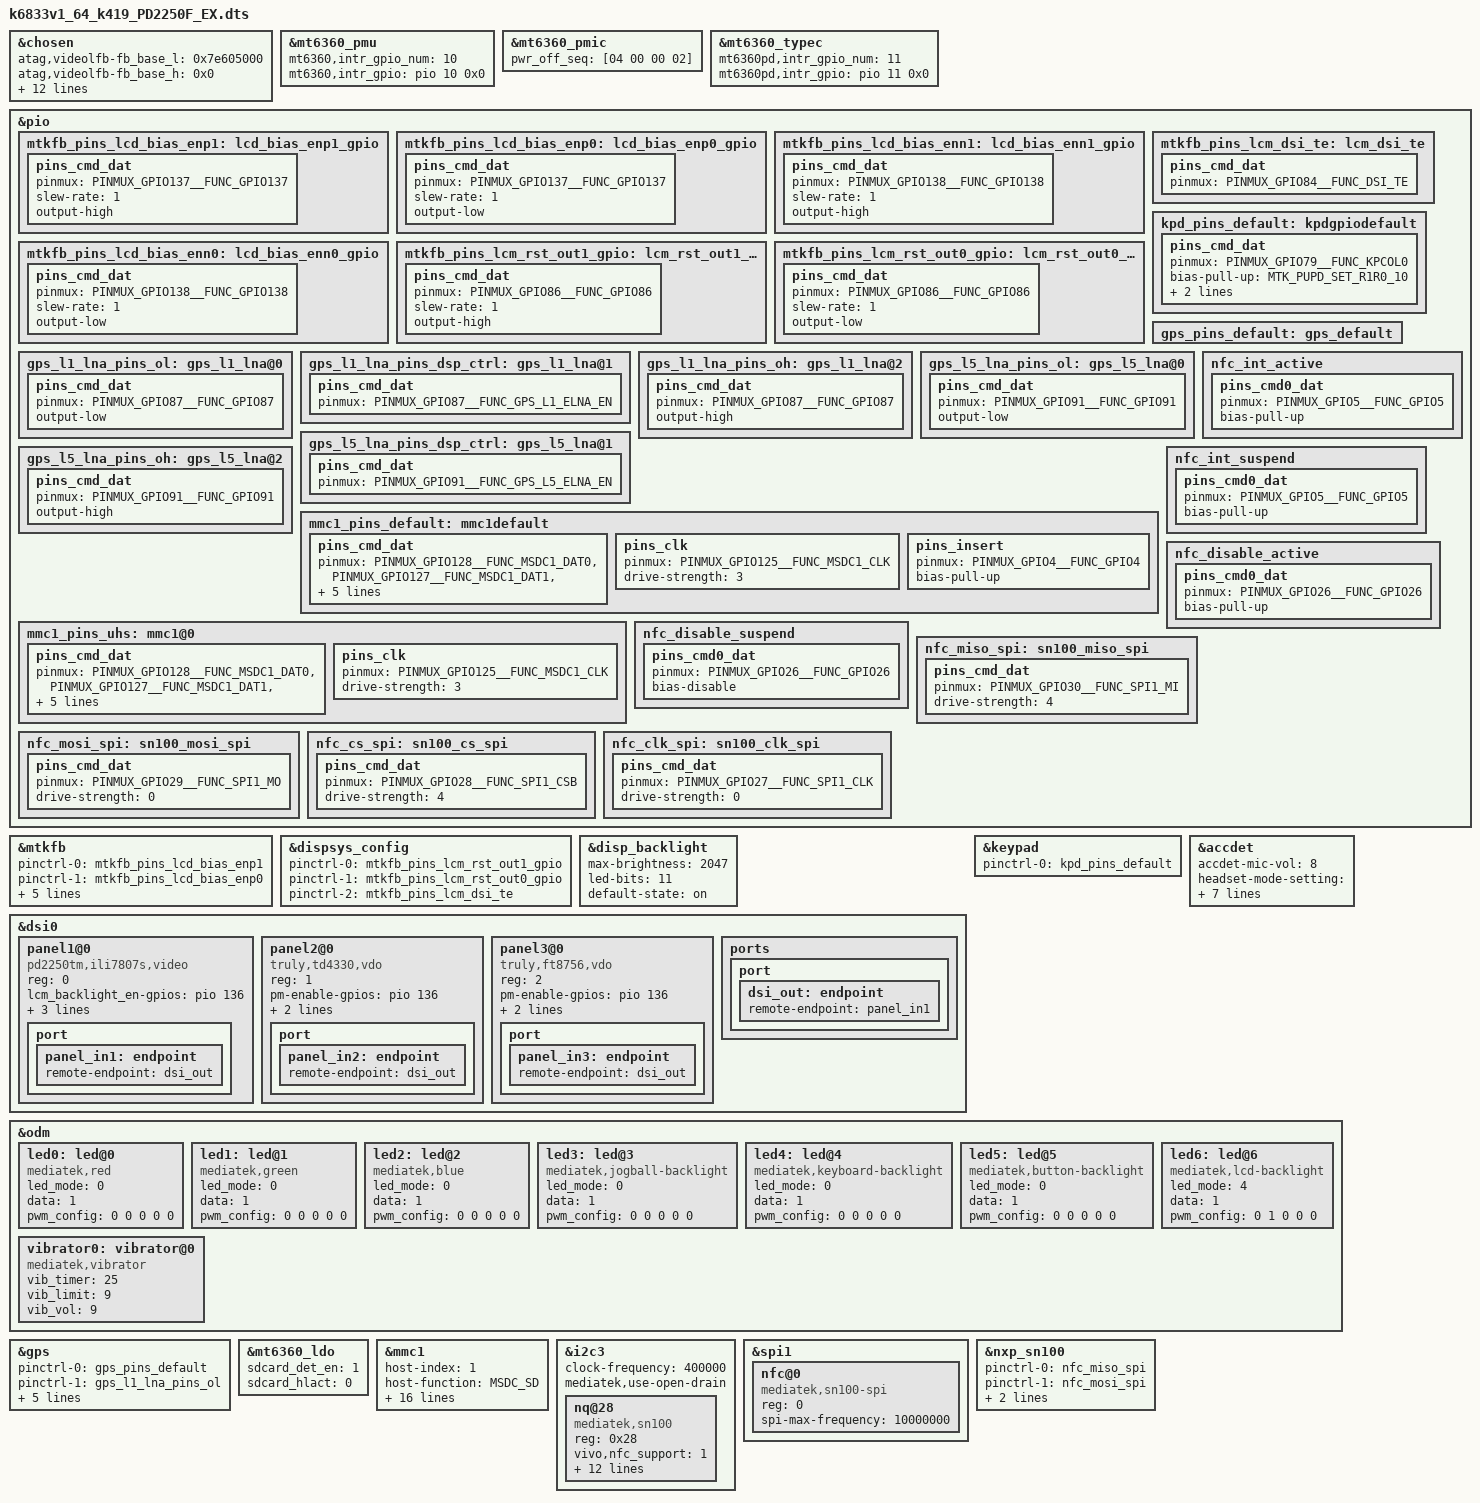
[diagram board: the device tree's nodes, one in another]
// SPDX-License-Identifier: GPL-2.0
/*
 * Copyright (c) 2019 MediaTek Inc.
 *
 */
/dts-v1/;
/plugin/;
#include <generated/autoconf.h>
#include <dt-bindings/interrupt-controller/irq.h>
#include <dt-bindings/interrupt-controller/arm-gic.h>
#include <dt-bindings/gpio/gpio.h>
#ifndef CONFIG_FPGA_EARLY_PORTING
#include <dt-bindings/pinctrl/mt6833-pinfunc.h>
#endif
#include "mediatek/fingerprint/mt6833-vivo-fp-PD2250F_EX.dtsi"
#include <dt-bindings/mmc/mt6833-msdc.h>

/* chosen */
&chosen {
	atag,videolfb-fb_base_l = <0x7e605000>;
	atag,videolfb-fb_base_h = <0x0>;
	atag,videolfb-islcmfound = <1>;
	atag,videolfb-islcm_inited = <0>;
	atag,videolfb-fps= <6000>;
	atag,videolfb-vramSize= <0x1be0000>;
	atag,videolfb-lcmname=
		"nt35595_fhd_dsi_cmd_truly_nt50358_drv";
	atag,videolfb-project-name= "pd2250";
	atag,vivo-dsi-panel-type = "super_tft";
	atag,exception-event-support;
	default-backlight-level = <1600>;
	bias-ic-use-i2c = <6>;
	bl-ic-use-i2c = <6>;
};

&mt6360_pmu {
	mt6360,intr_gpio_num = <10>; /* direct defined GPIO num */
	mt6360,intr_gpio = <&pio 10 0x0>;
};

&mt6360_pmic {
	pwr_off_seq = [04 00 00 02];
};

&mt6360_typec {
	mt6360pd,intr_gpio_num = <11>; /* direct defined GPIO num */
	mt6360pd,intr_gpio = <&pio 11 0x0>;
};

#ifndef CONFIG_FPGA_EARLY_PORTING
&pio {
	mtkfb_pins_lcd_bias_enp1: lcd_bias_enp1_gpio {
		pins_cmd_dat {
			pinmux = <PINMUX_GPIO137__FUNC_GPIO137>;
			slew-rate = <1>;
			output-high;
		};
	};

	mtkfb_pins_lcd_bias_enp0: lcd_bias_enp0_gpio {
		pins_cmd_dat {
			pinmux = <PINMUX_GPIO137__FUNC_GPIO137>;
			slew-rate = <1>;
			output-low;
		};
	};

	mtkfb_pins_lcd_bias_enn1: lcd_bias_enn1_gpio {
		pins_cmd_dat {
			pinmux = <PINMUX_GPIO138__FUNC_GPIO138>;
			slew-rate = <1>;
			output-high;
		};
	};

	mtkfb_pins_lcd_bias_enn0: lcd_bias_enn0_gpio {
		pins_cmd_dat {
			pinmux = <PINMUX_GPIO138__FUNC_GPIO138>;
			slew-rate = <1>;
			output-low;
		};
	};

	mtkfb_pins_lcm_rst_out1_gpio: lcm_rst_out1_gpio {
		pins_cmd_dat {
			pinmux = <PINMUX_GPIO86__FUNC_GPIO86>;
			slew-rate = <1>;
			output-high;
		};
	};

	mtkfb_pins_lcm_rst_out0_gpio: lcm_rst_out0_gpio {
		pins_cmd_dat {
			pinmux = <PINMUX_GPIO86__FUNC_GPIO86>;
			slew-rate = <1>;
			output-low;
		};
	};
	mtkfb_pins_lcm_dsi_te: lcm_dsi_te {
		pins_cmd_dat {
			pinmux = <PINMUX_GPIO84__FUNC_DSI_TE>;
		};
	};
};

&mtkfb {
	pinctrl-names = "lcd_bias_enp1_gpio", "lcd_bias_enp0_gpio",
		"lcd_bias_enn1_gpio", "lcd_bias_enn0_gpio",
		"lcm_rst_out1_gpio", "lcm_rst_out0_gpio",
		"mode_te_te";
	pinctrl-0 = <&mtkfb_pins_lcd_bias_enp1>;
	pinctrl-1 = <&mtkfb_pins_lcd_bias_enp0>;
	pinctrl-2 = <&mtkfb_pins_lcd_bias_enn1>;
	pinctrl-3 = <&mtkfb_pins_lcd_bias_enn0>;
	pinctrl-4 = <&mtkfb_pins_lcm_rst_out1_gpio>;
	pinctrl-5 = <&mtkfb_pins_lcm_rst_out0_gpio>;
	pinctrl-6 = <&mtkfb_pins_lcm_dsi_te>;
	status = "okay";
};
&dispsys_config {
	pinctrl-names =
		"lcm_rst_out1_gpio", "lcm_rst_out0_gpio",
		"mode_te_te";
	pinctrl-0 = <&mtkfb_pins_lcm_rst_out1_gpio>;
	pinctrl-1 = <&mtkfb_pins_lcm_rst_out0_gpio>;
	pinctrl-2 = <&mtkfb_pins_lcm_dsi_te>;
	status = "okay";
};

&disp_backlight {
	max-brightness = <2047>;
	led-bits = <11>;
	default-state = "on";
};

&dsi0 {
	status = "okay";
	#address-cells = <1>;
	#size-cells = <0>;
	panel1@0 {
		compatible = "pd2250tm,ili7807s,video";
		reg = <0>;
		lcm_backlight_en-gpios = <&pio 136 0>;
		lcm_reset-gpios = <&pio 86 0>;
		lcm_avdd_en-gpios = <&pio 137 0>;
		lcm_avee_en-gpios = <&pio 138 0>;
		pinctrl-names = "default";
		port {
			panel_in1: endpoint {
				remote-endpoint = <&dsi_out>;
			};
		};
	};
	panel2@0 {
		compatible = "truly,td4330,vdo";
		reg = <1>;
		pm-enable-gpios = <&pio 136 0>;
		reset-gpios = <&pio 86 0>;
		bias-gpios = <&pio 137 0>,
			<&pio 138 0>;
		pinctrl-names = "default";
		port {
			panel_in2: endpoint {
				remote-endpoint = <&dsi_out>;
			};
		};
	};
	panel3@0 {
		compatible = "truly,ft8756,vdo";
		reg = <2>;
		pm-enable-gpios = <&pio 136 0>;
		reset-gpios = <&pio 86 0>;
		bias-gpios = <&pio 137 0>,
			<&pio 138 0>;
		pinctrl-names = "default";
		port {
			panel_in3: endpoint {
				remote-endpoint = <&dsi_out>;
			};
		};
	};
	ports {
		port {
			dsi_out: endpoint {
				remote-endpoint = <&panel_in1>;
			};
		};
	};
};
#endif

&keypad {
	pinctrl-names = "default";
	pinctrl-0 = <&kpd_pins_default>;
};

&pio {
	kpd_pins_default: kpdgpiodefault {
		pins_cmd_dat {
			pinmux = <PINMUX_GPIO79__FUNC_KPCOL0>;
			bias-pull-up = <MTK_PUPD_SET_R1R0_10>;
			output-low;
			input-schmitt-enable;
		};
	};
};


/* accdet start */
&accdet {
	/* accdet micbias voltage: 0x09:2.85v 0x08:2.8v 0x07,
	 * 2.7v;0x05,2.5v;0x02,1.9v
	 */
	accdet-mic-vol = <8>;
	/* accdet pwm_width, pwm_thresh, fall_delay, rise_delay
	 * debounce0, debounce1, debounce3, debounce4
	 * eint pwm_width, eint pwm_thresh
	 * eint deb(debounce0, debounce1, debounce2, debounce3), inv_debounce
	 */
	headset-mode-setting = <0x500 0x500 1 0x1f0
				0x800 0x800 0x20 0x44
				0x4 0x1
				0x5 0x3 0x3 0x5 0xe>;
	accdet-plugout-debounce = <1>;
	/*1:ACC mode, 2:low cost without in bias, 6:low cost with in bias*/
	accdet-mic-mode = <2>;
	/*0--MD_MAX--UP_MAX--DW_MAX*/
	headset-three-key-threshold = <0 80 220 400>;
	headset-three-key-threshold-CDD = <0 121 192 600>;
	/*0--MD_MAX--VOICE_MAX--UP_MAX--DW_MAX*/
	headset-four-key-threshold = <0 58 121 192 400>;

	/* select VTH to 2v and 500k, use internal resitance */
	eint_use_ext_res = <0>;
	status = "okay";
};
/* accdet end */

&odm {
	led0:led@0 {
		compatible = "mediatek,red";
		led_mode = <0>;
		data = <1>;
		pwm_config = <0 0 0 0 0>;
	};
	led1:led@1 {
		compatible = "mediatek,green";
		led_mode = <0>;
		data = <1>;
		pwm_config = <0 0 0 0 0>;
	};
	led2:led@2 {
		compatible = "mediatek,blue";
		led_mode = <0>;
		data = <1>;
		pwm_config = <0 0 0 0 0>;
	};
	led3:led@3 {
		compatible = "mediatek,jogball-backlight";
		led_mode = <0>;
		data = <1>;
		pwm_config = <0 0 0 0 0>;
	};
	led4:led@4 {
		compatible = "mediatek,keyboard-backlight";
		led_mode = <0>;
		data = <1>;
		pwm_config = <0 0 0 0 0>;
	};
	led5:led@5 {
		compatible = "mediatek,button-backlight";
		led_mode = <0>;
		data = <1>;
		pwm_config = <0 0 0 0 0>;
	};
	led6:led@6 {
		compatible = "mediatek,lcd-backlight";
		led_mode = <4>; /*5:cpu pwm 4:lcm pwm*/
		data = <1>;
		pwm_config = <0 1 0 0 0>;
	};
	vibrator0:vibrator@0 {
		compatible = "mediatek,vibrator";
		vib_timer = <25>;
		vib_limit = <9>;
		vib_vol= <9>;
	};
};
/* GPS GPIO standardization start */
&pio {
	gps_pins_default: gps_default {
	};

	gps_l1_lna_pins_ol: gps_l1_lna@0 {
		pins_cmd_dat {
			pinmux = <PINMUX_GPIO87__FUNC_GPIO87>;
			output-low;
		};
	};
	gps_l1_lna_pins_dsp_ctrl: gps_l1_lna@1 {
		pins_cmd_dat {
			pinmux = <PINMUX_GPIO87__FUNC_GPS_L1_ELNA_EN>;
		};
	};
	gps_l1_lna_pins_oh: gps_l1_lna@2 {
		pins_cmd_dat {
			pinmux = <PINMUX_GPIO87__FUNC_GPIO87>;
			output-high;
		};
	};

	gps_l5_lna_pins_ol: gps_l5_lna@0 {
		pins_cmd_dat {
			pinmux = <PINMUX_GPIO91__FUNC_GPIO91>;
			output-low;
		};
	};
	gps_l5_lna_pins_dsp_ctrl: gps_l5_lna@1 {
		pins_cmd_dat {
			pinmux = <PINMUX_GPIO91__FUNC_GPS_L5_ELNA_EN>;
		};
	};
	gps_l5_lna_pins_oh: gps_l5_lna@2 {
		pins_cmd_dat {
			pinmux = <PINMUX_GPIO91__FUNC_GPIO91>;
			output-high;
		};
	};
};

&gps {
	pinctrl-names = "default",
		"gps_l1_lna_disable",
		"gps_l1_lna_dsp_ctrl",
		"gps_l1_lna_enable",
		"gps_l5_lna_disable",
		"gps_l5_lna_dsp_ctrl",
		"gps_l5_lna_enable";
	pinctrl-0 = <&gps_pins_default>;
	pinctrl-1 = <&gps_l1_lna_pins_ol>;
	pinctrl-2 = <&gps_l1_lna_pins_dsp_ctrl>;
	pinctrl-3 = <&gps_l1_lna_pins_oh>;
	pinctrl-4 = <&gps_l5_lna_pins_ol>;
	pinctrl-5 = <&gps_l5_lna_pins_dsp_ctrl>;
	pinctrl-6 = <&gps_l5_lna_pins_oh>;
	status = "okay";
};
/* GPS GPIO standardization end */
#include "mediatek/cust_mt6833_camera.dtsi"
#include "mediatek/cust_vivo_PD2250F_EX.dtsi"
#include "mediatek/vivo_tp_setting/mtk-vivo-tp-PD2250F_EX.dtsi"


/*End of this file, DO NOT ADD ANYTHING HERE*/

&mt6360_ldo {
	sdcard_det_en = <1>;
	sdcard_hlact = <0>;
};

&mmc1 {
	status = "okay";
	host-index = <1>;
	host-function = <MSDC_SD>;
	pinctrl-names = "default", "state_uhs";
	pinctrl-0 = <&mmc1_pins_default>;
	pinctrl-1 = <&mmc1_pins_uhs>;
	bus-width = <4>;
	max-frequency = <200000000>;
	cap-sd-highspeed;
	sd-uhs-sdr12;
	sd-uhs-sdr25;
	sd-uhs-sdr50;
	sd-uhs-sdr104;
	sd-uhs-ddr50;
	cd-gpios = <&pio 4 GPIO_ACTIVE_HIGH>;
	vmmc-supply = <&mt_pmic_vmch_ldo_reg>;
	vqmmc-supply = <&mt_pmic_vmc_ldo_reg>;
	fast_power_off;
	no-mmc;
	no-sdio;
};

&pio {
	mmc1_pins_default: mmc1default {
		pins_cmd_dat {
			pinmux = <PINMUX_GPIO128__FUNC_MSDC1_DAT0>,
				<PINMUX_GPIO127__FUNC_MSDC1_DAT1>,
				<PINMUX_GPIO129__FUNC_MSDC1_DAT2>,
				<PINMUX_GPIO130__FUNC_MSDC1_DAT3>,
				<PINMUX_GPIO126__FUNC_MSDC1_CMD>;
			input-enable;
			drive-strength = <3>;
		};

		pins_clk {
			pinmux = <PINMUX_GPIO125__FUNC_MSDC1_CLK>;
			drive-strength = <3>;
		};

		pins_insert {
			pinmux = <PINMUX_GPIO4__FUNC_GPIO4>;
			bias-pull-up;
		};
	};

	mmc1_pins_uhs: mmc1@0{
		pins_cmd_dat {
			pinmux = <PINMUX_GPIO128__FUNC_MSDC1_DAT0>,
				<PINMUX_GPIO127__FUNC_MSDC1_DAT1>,
				<PINMUX_GPIO129__FUNC_MSDC1_DAT2>,
				<PINMUX_GPIO130__FUNC_MSDC1_DAT3>,
				<PINMUX_GPIO126__FUNC_MSDC1_CMD>;
			input-enable;
			drive-strength = <3>;
		};

		pins_clk {
			pinmux = <PINMUX_GPIO125__FUNC_MSDC1_CLK>;
			drive-strength = <3>;
		};
	};
};

/* NFC GPIO standardization begin*/
&pio {
	nfc_int_active: nfc_int_active {
		pins_cmd0_dat {
			pinmux = <PINMUX_GPIO5__FUNC_GPIO5>;
			bias-pull-up;
		};
	};
	nfc_int_suspend: nfc_int_suspend {
		pins_cmd0_dat {
			pinmux = <PINMUX_GPIO5__FUNC_GPIO5>;
			bias-pull-up;
		};
	};
	nfc_disable_active: nfc_disable_active {
		pins_cmd0_dat {
			pinmux = <PINMUX_GPIO26__FUNC_GPIO26>;
			bias-pull-up;
		};
	};
	nfc_disable_suspend: nfc_disable_suspend {
		pins_cmd0_dat {
			pinmux = <PINMUX_GPIO26__FUNC_GPIO26>;
			bias-disable;
		};
	};

};
&i2c3 {
	status = "okay";
	#address-cells = <1>;
	#size-cells = <0>;
	clock-frequency = <400000>;
	mediatek,use-open-drain;
	nq@28 {
		compatible = "mediatek,sn100";
		reg = <0x28>;
		vivo,nfc_support = <1>;
		vivo,boardversion_shift = <0>;
		vivo,boardversion_mask = <0>;
		vivo,boardversion_num = <0>;
		vivo,boardversions = "0";
		vivo,nfc_chip_type = "SN220T";
		mediatek,nq-irq = <&pio 5 0x00>;
		mediatek,nq-ven = <&pio 26 0x00>;
		//mediatek,nq-firm = <&pio -1 0x00>;
		//mediatek,nq-clkreq = <&pio 81 0x00>;
		interrupt-parent = <&pio>;
		interrupts = <5 0>;
		interrupt-names = "nfc_irq";
		pinctrl-names = "nfc_active", "nfc_suspend";
		pinctrl-0 = <&nfc_int_active &nfc_disable_active>;
		pinctrl-1 = <&nfc_int_suspend &nfc_disable_suspend>;
	};
};
/* NFC GPIO standardization end*/
/* NFC SPI standardization begin*/
&spi1 {
	#address-cells = <1>;
	#size-cells = <0>;
	nfc@0 {
		compatible = "mediatek,sn100-spi";
		reg = <0>;
		spi-max-frequency = <10000000>;
		status = "okay";
	};
};

&nxp_sn100 {
    status = "okay";
	pinctrl-names = "miso_spi","mosi_spi","cs_spi","clk_spi";
	pinctrl-0 = <&nfc_miso_spi>;
	pinctrl-1 = <&nfc_mosi_spi>;
	pinctrl-2 = <&nfc_cs_spi>;
	pinctrl-3 = <&nfc_clk_spi>;

};

&pio {
	nfc_miso_spi: sn100_miso_spi {
		pins_cmd_dat {
			pinmux = <PINMUX_GPIO30__FUNC_SPI1_MI>;
			drive-strength = <4>;
		};
	};
	nfc_mosi_spi: sn100_mosi_spi {
		pins_cmd_dat {
			pinmux = <PINMUX_GPIO29__FUNC_SPI1_MO>;
			drive-strength = <0>;
		};
	};
	nfc_cs_spi: sn100_cs_spi {
		pins_cmd_dat {
			pinmux = <PINMUX_GPIO28__FUNC_SPI1_CSB>;
			drive-strength = <4>;
			//bias-pull-up;
		};
	};
	nfc_clk_spi: sn100_clk_spi {
		pins_cmd_dat {
			pinmux = <PINMUX_GPIO27__FUNC_SPI1_CLK>;
			drive-strength = <0>;
		};
	};
};
/* NFC SPI standardization end*/
